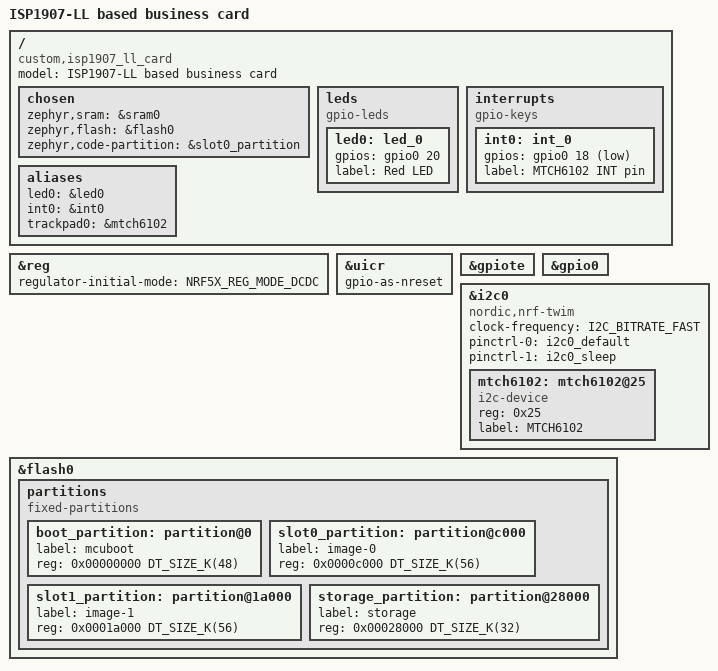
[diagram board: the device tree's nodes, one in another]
/dts-v1/;
#include <nordic/nrf52811_qfaa.dtsi>
#include "isp1907_ll_card-pinctrl.dtsi"

/ {
	model = "ISP1907-LL based business card";
	compatible = "custom,isp1907_ll_card";

	chosen {
		zephyr,sram = &sram0;
		zephyr,flash = &flash0;
		zephyr,code-partition = &slot0_partition;
	};

	leds {
		compatible = "gpio-leds";
		led0: led_0 {
			gpios = <&gpio0 20 (GPIO_PULL_DOWN | GPIO_ACTIVE_HIGH)>;
			label = "Red LED";
		};
	};

	interrupts {
		compatible = "gpio-keys";
		int0: int_0 {
			gpios = <&gpio0 18 GPIO_ACTIVE_LOW>;
			label = "MTCH6102 INT pin";
		};
	};

	aliases {
		led0 = &led0;
		int0 = &int0;
		trackpad0 = &mtch6102;
	};
};

&reg {
	regulator-initial-mode = <NRF5X_REG_MODE_DCDC>;
};

&uicr {
	gpio-as-nreset;
};

&gpiote {
	status = "okay";
};

&gpio0 {
	status = "okay";
};

&i2c0 {
	compatible = "nordic,nrf-twim";
	status = "okay";
	clock-frequency = <I2C_BITRATE_FAST>;
	pinctrl-0 = <&i2c0_default>;
	pinctrl-1 = <&i2c0_sleep>;
	pinctrl-names = "default", "sleep";

	mtch6102: mtch6102@25 {
		compatible = "i2c-device";
		reg = <0x25>;
		label = "MTCH6102";
		// int-gpios = <&gpio0 18 (GPIO_PULL_UP | GPIO_ACTIVE_LOW)>;
	};
};

&flash0 {
	partitions {
		compatible = "fixed-partitions";
		#address-cells = <1>;
		#size-cells = <1>;

		boot_partition: partition@0 {
			label = "mcuboot";
			reg = <0x00000000 DT_SIZE_K(48)>;
		};

		slot0_partition: partition@c000 {
			label = "image-0";
			reg = <0x0000c000 DT_SIZE_K(56)>;
		};

		slot1_partition: partition@1a000 {
			label = "image-1";
			reg = <0x0001a000 DT_SIZE_K(56)>;
		};

		storage_partition: partition@28000 {
			label = "storage";
			reg = <0x00028000 DT_SIZE_K(32)>;
		};
	};
};
